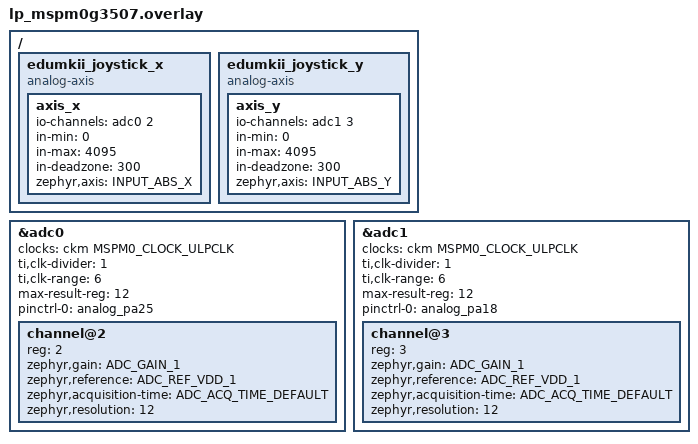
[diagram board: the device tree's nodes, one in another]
/*
 * LP-MSPM0G3507, BoosterPack header.
 * Joystick X (pin 2) is PA25 = ADC0 channel 2. Joystick Y (pin 26) is PA18 =
 * ADC1 channel 3 and PA18 is also the LaunchPad S1 button: pull J8 first.
 * S1 (pin 33) is PA11, which is the backchannel UART RX until J22 moves to 2-3.
 *
 * SPDX-License-Identifier: Apache-2.0
 */

#include <boosterpack/lp_mspm0g3507.dtsi>
#include <zephyr/dt-bindings/clock/mspm0_clock.h>
#include <zephyr/dt-bindings/adc/adc.h>
#include <zephyr/dt-bindings/input/input-event-codes.h>

&adc0 {
	clocks = <&ckm MSPM0_CLOCK_ULPCLK>;
	ti,clk-divider = <1>;
	ti,clk-range = <6>;
	max-result-reg = <12>;
	pinctrl-0 = <&analog_pa25>;
	pinctrl-names = "default";
	status = "okay";
	#address-cells = <1>;
	#size-cells = <0>;

	channel@2 {
		reg = <2>;
		zephyr,gain = "ADC_GAIN_1";
		zephyr,reference = "ADC_REF_VDD_1";
		zephyr,acquisition-time = <ADC_ACQ_TIME_DEFAULT>;
		zephyr,resolution = <12>;
	};
};

&adc1 {
	clocks = <&ckm MSPM0_CLOCK_ULPCLK>;
	ti,clk-divider = <1>;
	ti,clk-range = <6>;
	max-result-reg = <12>;
	pinctrl-0 = <&analog_pa18>;
	pinctrl-names = "default";
	status = "okay";
	#address-cells = <1>;
	#size-cells = <0>;

	channel@3 {
		reg = <3>;
		zephyr,gain = "ADC_GAIN_1";
		zephyr,reference = "ADC_REF_VDD_1";
		zephyr,acquisition-time = <ADC_ACQ_TIME_DEFAULT>;
		zephyr,resolution = <12>;
	};
};

/ {
	/* One ADC per node: X on ADC0, Y on ADC1. */
	edumkii_joystick_x {
		compatible = "analog-axis";

		axis_x {
			io-channels = <&adc0 2>;
			in-min = <0>;
			in-max = <4095>;
			in-deadzone = <300>;
			zephyr,axis = <INPUT_ABS_X>;
		};
	};

	edumkii_joystick_y {
		compatible = "analog-axis";

		axis_y {
			io-channels = <&adc1 3>;
			in-min = <0>;
			in-max = <4095>;
			in-deadzone = <300>;
			zephyr,axis = <INPUT_ABS_Y>;
		};
	};
};

#include "../common.dtsi"
